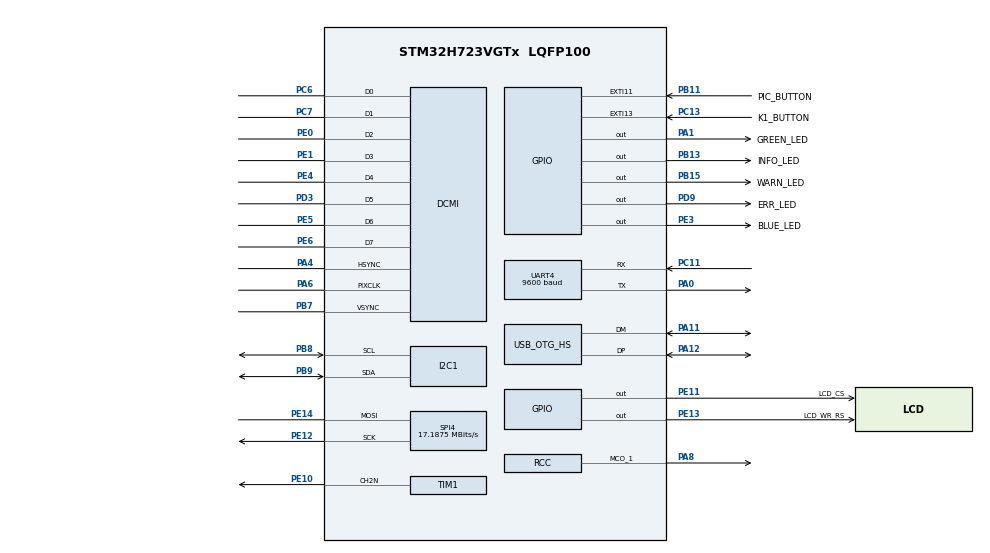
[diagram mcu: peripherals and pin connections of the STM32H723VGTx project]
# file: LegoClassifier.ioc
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CORTEX_M7.default_mode_Activation=1
DCMI.PCKPolarity=DCMI_PCKPOLARITY_RISING
Dma.DCMI.0.Direction=DMA_PERIPH_TO_MEMORY
Dma.DCMI.0.EventEnable=DISABLE
Dma.DCMI.0.FIFOMode=DMA_FIFOMODE_DISABLE
Dma.DCMI.0.Instance=DMA1_Stream0
Dma.DCMI.0.MemDataAlignment=DMA_MDATAALIGN_WORD
Dma.DCMI.0.MemInc=DMA_MINC_ENABLE
Dma.DCMI.0.Mode=DMA_CIRCULAR
Dma.DCMI.0.PeriphDataAlignment=DMA_PDATAALIGN_WORD
Dma.DCMI.0.PeriphInc=DMA_PINC_DISABLE
Dma.DCMI.0.Polarity=HAL_DMAMUX_REQ_GEN_RISING
Dma.DCMI.0.Priority=DMA_PRIORITY_MEDIUM
Dma.DCMI.0.RequestNumber=1
Dma.DCMI.0.SignalID=NONE
Dma.DCMI.0.SyncEnable=DISABLE
Dma.DCMI.0.SyncPolarity=HAL_DMAMUX_SYNC_NO_EVENT
Dma.DCMI.0.SyncRequestNumber=1
Dma.DCMI.0.SyncSignalID=NONE
Dma.Request0=DCMI
FREERTOS.Mutexes01=usb_mutex,Dynamic,NULL,Available;core_dump_mutex,Dynamic,NULL,Available
FREERTOS.Tasks01=defaultTask,0,6144,StartDefaultTask,Default,NULL,Static,defaultTaskBuffer,defaultTaskControlBlock
I2C1.Timing=0x60404E72
IWDG1.Prescaler=IWDG_PRESCALER_256
Mcu.Family=STM32H7
Mcu.Name=STM32H723VGTx
Mcu.Package=LQFP100
NVIC.DCMI_PSSI_IRQn=true\:5\:0\:false\:false\:true\:true\:true\:true\:true
NVIC.DMA1_Stream0_IRQn=true\:5\:0\:false\:false\:true\:true\:false\:true\:true
NVIC.EXTI15_10_IRQn=true\:5\:0\:false\:false\:true\:true\:true\:true\:true
NVIC.OTG_HS_IRQn=true\:5\:0\:false\:false\:true\:true\:false\:true\:true
NVIC.PriorityGroup=NVIC_PRIORITYGROUP_4
NVIC.TIM2_IRQn=true\:15\:0\:false\:false\:true\:false\:false\:true\:true
NVIC.TimeBase=TIM2_IRQn
NVIC.TimeBaseIP=TIM2
PA0.Mode=Asynchronous
PA0.Signal=UART4_TX
PA1.GPIO_Label=GREEN_LED
PA1.Signal=GPIO_Output
PA11.Mode=Device_Only_FS
PA11.Signal=USB_OTG_HS_DM
PA12.Mode=Device_Only_FS
PA12.Signal=USB_OTG_HS_DP
PA13(JTMS/SWDIO).Mode=Serial_Wire
PA13(JTMS/SWDIO).Signal=DEBUG_JTMS-SWDIO
PA14(JTCK/SWCLK).Mode=Serial_Wire
PA14(JTCK/SWCLK).Signal=DEBUG_JTCK-SWCLK
PA4.Mode=Slave_8_bits_External_Synchro
PA4.Signal=DCMI_HSYNC
PA6.Mode=Slave_8_bits_External_Synchro
PA6.Signal=DCMI_PIXCLK
PA8.Mode=Clock-out-1
PA8.Signal=RCC_MCO_1
PB11.GPIO_Label=PIC_BUTTON
PB11.GPIO_PuPd=GPIO_PULLDOWN
PB11.Signal=GPXTI11
PB13.GPIO_Label=INFO_LED
PB13.GPIO_PuPd=GPIO_PULLDOWN
PB13.Signal=GPIO_Output
PB15.GPIO_Label=WARN_LED
PB15.GPIO_PuPd=GPIO_PULLDOWN
PB15.Signal=GPIO_Output
PB7.Mode=Slave_8_bits_External_Synchro
PB7.Signal=DCMI_VSYNC
PB8.Mode=I2C
PB8.Signal=I2C1_SCL
PB9.Mode=I2C
PB9.Signal=I2C1_SDA
PC11.Mode=Asynchronous
PC11.Signal=UART4_RX
PC13.GPIO_Label=K1_BUTTON
PC13.GPIO_ModeDefaultEXTI=GPIO_MODE_IT_RISING
PC13.GPIO_PuPd=GPIO_PULLDOWN
PC13.Signal=GPXTI13
PC14-OSC32_IN.Mode=LSE-External-Oscillator
PC14-OSC32_IN.Signal=RCC_OSC32_IN
PC15-OSC32_OUT.Mode=LSE-External-Oscillator
PC15-OSC32_OUT.Signal=RCC_OSC32_OUT
PC6.Mode=Slave_8_bits_External_Synchro
PC6.Signal=DCMI_D0
PC7.Mode=Slave_8_bits_External_Synchro
PC7.Signal=DCMI_D1
PD3.Mode=Slave_8_bits_External_Synchro
PD3.Signal=DCMI_D5
PD9.GPIO_Label=ERR_LED
PD9.GPIO_PuPd=GPIO_PULLDOWN
PD9.Signal=GPIO_Output
PE0.Mode=Slave_8_bits_External_Synchro
PE0.Signal=DCMI_D2
PE1.Mode=Slave_8_bits_External_Synchro
PE1.Signal=DCMI_D3
PE10.Mode=PWM Generation2 CH2N
PE10.Signal=TIM1_CH2N
PE11.GPIO_Label=LCD_CS
PE11.Signal=GPIO_Output
PE12.Mode=Simplex_Bidirectional_Master
PE12.Signal=SPI4_SCK
PE13.GPIO_Label=LCD_WR_RS
PE13.Signal=GPIO_Output
PE14.Mode=Simplex_Bidirectional_Master
PE14.Signal=SPI4_MOSI
PE3.GPIO_Label=BLUE_LED
PE3.Signal=GPIO_Output
PE4.Mode=Slave_8_bits_External_Synchro
PE4.Signal=DCMI_D4
PE5.Mode=Slave_8_bits_External_Synchro
PE5.Signal=DCMI_D6
PE6.Mode=Slave_8_bits_External_Synchro
PE6.Signal=DCMI_D7
PH0-OSC_IN.Mode=HSE-External-Oscillator
PH0-OSC_IN.Signal=RCC_OSC_IN
PH1-OSC_OUT.Mode=HSE-External-Oscillator
PH1-OSC_OUT.Signal=RCC_OSC_OUT
ProjectManager.HeapSize=0x200
ProjectManager.StackSize=0x400
ProjectManager.TargetToolchain=CMake
RCC.ADCFreq_Value=50390625
RCC.APB1Freq_Value=137500000
RCC.APB2Freq_Value=137500000
RCC.APB3Freq_Value=137500000
RCC.APB4Freq_Value=137500000
RCC.CortexFreq_Value=550000000
RCC.D1PPRE=RCC_APB3_DIV2
RCC.D2PPRE1=RCC_APB1_DIV2
RCC.D2PPRE2=RCC_APB2_DIV2
RCC.D3PPRE=RCC_APB4_DIV2
RCC.DIVM1=2
RCC.DIVN1=44
RCC.DIVP1=1
RCC.DIVQ1=46
RCC.HCLKFreq_Value=275000000
RCC.HPRE=RCC_HCLK_DIV2
RCC.PLL2FRACN=0
RCC.PLL3FRACN=0
RCC.PLLFRACN=0
RCC.PLLSourceVirtual=RCC_PLLSOURCE_HSE
RCC.RCC_MCO1Source=RCC_MCO1SOURCE_HSI48
RCC.RCC_MCODiv1=RCC_MCODIV_4
RCC.SYSCLKFreq_VALUE=550000000
RCC.SYSCLKSource=RCC_SYSCLKSOURCE_PLLCLK
RCC.USBCLockSelection=RCC_USBCLKSOURCE_HSI48
RCC.USBFreq_Value=48000000
SPI4.BaudRatePrescaler=SPI_BAUDRATEPRESCALER_8
SPI4.CalculateBaudRate=17.1875 MBits/s
SPI4.DataSize=SPI_DATASIZE_8BIT
SPI4.Direction=SPI_DIRECTION_1LINE
SPI4.Mode=SPI_MODE_MASTER
SPI4.VirtualType=VM_MASTER
TIM1.Channel-PWM\ Generation2\ CH2N=TIM_CHANNEL_2
TIM1.OCNPolarity_2=TIM_OCNPOLARITY_LOW
TIM1.Period=1000-1
TIM1.Prescaler=14-1
UART4.BaudRate=9600
USB_DEVICE.CLASS_NAME_HS=CDC
USB_DEVICE.PRODUCT_STRING_CDC_HS=STM32 LegoClassifier
USB_DEVICE.VID=8743
USB_DEVICE.VirtualMode=Cdc
USB_DEVICE.VirtualModeHS=Cdc_HS
USB_OTG_HS.VirtualMode-Device_Only_FS=Device_Only_FS
VP_FREERTOS_VS_CMSIS_V1.Mode=CMSIS_V1
VP_IWDG1_VS_IWDG.Mode=IWDG_Activate
VP_MEMORYMAP_VS_MEMORYMAP.Mode=CurAppReg
VP_RTC_VS_RTC_Activate.Mode=RTC_Enabled
VP_RTC_VS_RTC_Calendar.Mode=RTC_Calendar
VP_SYS_VS_tim2.Mode=TIM2
VP_USB_DEVICE_VS_USB_DEVICE_CDC_HS.Mode=CDC_HS
board=custom

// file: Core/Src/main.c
/* USER CODE BEGIN Header */
/**
  ******************************************************************************
  * @file           : main.c
  * @brief          : Main program body
  ******************************************************************************
  * @attention
  *
  * Copyright (c) 2026 STMicroelectronics.
  * All rights reserved.
  *
  * This software is licensed under terms that can be found in the LICENSE file
  * in the root directory of this software component.
  * If no LICENSE file comes with this software, it is provided AS-IS.
  *
  ******************************************************************************
  */
/* USER CODE END Header */
#include "main.h"
#include "cmsis_os.h"
#include "dcmi.h"
#include "dma.h"
#include "i2c.h"
#include "iwdg.h"
#include "rtc.h"
#include "spi.h"
#include "tim.h"
#include "usart.h"
#include "usb_device.h"
#include "gpio.h"

/* USER CODE BEGIN Includes */
#include "app_entry.h"
/* USER CODE END Includes */

void SystemClock_Config(void);
static void MPU_Config(void);
void MX_FREERTOS_Init(void);

int main(void)
{

  /* MPU Configuration--------------------------------------------------------*/
  MPU_Config();

  /* MCU Configuration--------------------------------------------------------*/

  /* Reset of all peripherals, Initializes the Flash interface and the Systick. */
  HAL_Init();

  /* Configure the system clock */
  SystemClock_Config();

  /* Initialize all configured peripherals */
  MX_GPIO_Init();
  MX_DMA_Init();
  MX_I2C1_Init();
  MX_DCMI_Init();
  MX_SPI4_Init();
  MX_TIM1_Init();
  MX_IWDG1_Init();
  MX_RTC_Init();
  MX_UART4_Init();
  /* USER CODE BEGIN 2 */
  app_initiation();
  /* USER CODE END 2 */

  /* Call init function for freertos objects (in cmsis_os2.c) */
  MX_FREERTOS_Init();

  /* Start scheduler */
  osKernelStart();

  /* We should never get here as control is now taken by the scheduler */

  /* Infinite loop */
  while (1)
  {

  }
}

void SystemClock_Config(void)
{
  RCC_OscInitTypeDef RCC_OscInitStruct = {0};
  RCC_ClkInitTypeDef RCC_ClkInitStruct = {0};

  /** Supply configuration update enable
  */
  HAL_PWREx_ConfigSupply(PWR_LDO_SUPPLY);

  /** Configure the main internal regulator output voltage
  */
  __HAL_PWR_VOLTAGESCALING_CONFIG(PWR_REGULATOR_VOLTAGE_SCALE0);

  while(!__HAL_PWR_GET_FLAG(PWR_FLAG_VOSRDY)) {}

  /** Initializes the RCC Oscillators according to the specified parameters
  * in the RCC_OscInitTypeDef structure.
  */
  RCC_OscInitStruct.OscillatorType = RCC_OSCILLATORTYPE_HSI48|RCC_OSCILLATORTYPE_LSI
                              |RCC_OSCILLATORTYPE_HSE;
  RCC_OscInitStruct.HSEState = RCC_HSE_ON;
  RCC_OscInitStruct.LSIState = RCC_LSI_ON;
  RCC_OscInitStruct.HSI48State = RCC_HSI48_ON;
  RCC_OscInitStruct.PLL.PLLState = RCC_PLL_ON;
  RCC_OscInitStruct.PLL.PLLSource = RCC_PLLSOURCE_HSE;
  RCC_OscInitStruct.PLL.PLLM = 2;
  RCC_OscInitStruct.PLL.PLLN = 44;
  RCC_OscInitStruct.PLL.PLLP = 1;
  RCC_OscInitStruct.PLL.PLLQ = 46;
  RCC_OscInitStruct.PLL.PLLR = 2;
  RCC_OscInitStruct.PLL.PLLRGE = RCC_PLL1VCIRANGE_3;
  RCC_OscInitStruct.PLL.PLLVCOSEL = RCC_PLL1VCOWIDE;
  RCC_OscInitStruct.PLL.PLLFRACN = 0;
  if (HAL_RCC_OscConfig(&RCC_OscInitStruct) != HAL_OK)
  {
    Error_Handler();
  }

  /** Initializes the CPU, AHB and APB buses clocks
  */
  RCC_ClkInitStruct.ClockType = RCC_CLOCKTYPE_HCLK|RCC_CLOCKTYPE_SYSCLK
                              |RCC_CLOCKTYPE_PCLK1|RCC_CLOCKTYPE_PCLK2
                              |RCC_CLOCKTYPE_D3PCLK1|RCC_CLOCKTYPE_D1PCLK1;
  RCC_ClkInitStruct.SYSCLKSource = RCC_SYSCLKSOURCE_PLLCLK;
  RCC_ClkInitStruct.SYSCLKDivider = RCC_SYSCLK_DIV1;
  RCC_ClkInitStruct.AHBCLKDivider = RCC_HCLK_DIV2;
  RCC_ClkInitStruct.APB3CLKDivider = RCC_APB3_DIV2;
  RCC_ClkInitStruct.APB1CLKDivider = RCC_APB1_DIV2;
  RCC_ClkInitStruct.APB2CLKDivider = RCC_APB2_DIV2;
  RCC_ClkInitStruct.APB4CLKDivider = RCC_APB4_DIV2;

  if (HAL_RCC_ClockConfig(&RCC_ClkInitStruct, FLASH_LATENCY_3) != HAL_OK)
  {
    Error_Handler();
  }
  HAL_RCC_MCOConfig(RCC_MCO1, RCC_MCO1SOURCE_HSI48, RCC_MCODIV_4);
}

 /* MPU Configuration */

void MPU_Config(void)
{
  MPU_Region_InitTypeDef MPU_InitStruct = {0};

  /* Disables the MPU */
  HAL_MPU_Disable();

  /** Initializes and configures the Region and the memory to be protected
  */
  MPU_InitStruct.Enable = MPU_REGION_ENABLE;
  MPU_InitStruct.Number = MPU_REGION_NUMBER0;
  MPU_InitStruct.BaseAddress = 0x0;
  MPU_InitStruct.Size = MPU_REGION_SIZE_4GB;
  MPU_InitStruct.SubRegionDisable = 0x87;
  MPU_InitStruct.TypeExtField = MPU_TEX_LEVEL0;
  MPU_InitStruct.AccessPermission = MPU_REGION_NO_ACCESS;
  MPU_InitStruct.DisableExec = MPU_INSTRUCTION_ACCESS_DISABLE;
  MPU_InitStruct.IsShareable = MPU_ACCESS_SHAREABLE;
  MPU_InitStruct.IsCacheable = MPU_ACCESS_NOT_CACHEABLE;
  MPU_InitStruct.IsBufferable = MPU_ACCESS_NOT_BUFFERABLE;

  HAL_MPU_ConfigRegion(&MPU_InitStruct);
  /* Enables the MPU */
  HAL_MPU_Enable(MPU_PRIVILEGED_DEFAULT);

}

void HAL_TIM_PeriodElapsedCallback(TIM_HandleTypeDef *htim)
{
  if (htim->Instance == TIM2)
  {
    HAL_IncTick();
  }
}

void Error_Handler(void)
{
  /* USER CODE BEGIN Error_Handler_Debug */
  /* User can add his own implementation to report the HAL error return state */
  __disable_irq();
  while (1)
  {
    HAL_GPIO_TogglePin(ERR_LED_GPIO_Port, ERR_LED_Pin);
    HAL_Delay(200);
  }
  /* USER CODE END Error_Handler_Debug */
}

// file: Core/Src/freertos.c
/* USER CODE BEGIN Header */
/**
  ******************************************************************************
  * File Name          : freertos.c
  * Description        : Code for freertos applications
  ******************************************************************************
  * @attention
  *
  * Copyright (c) 2026 STMicroelectronics.
  * All rights reserved.
  *
  * This software is licensed under terms that can be found in the LICENSE file
  * in the root directory of this software component.
  * If no LICENSE file comes with this software, it is provided AS-IS.
  *
  ******************************************************************************
  */
/* USER CODE END Header */

#include "app_entry.h"
#include "FreeRTOS.h"
#include "task.h"
#include "main.h"
#include "cmsis_os.h"

osThreadId defaultTaskHandle;
uint32_t defaultTaskBuffer[ 6144 ];
osStaticThreadDef_t defaultTaskControlBlock;
osMutexId usb_mutexHandle;
osMutexId core_dump_mutexHandle;

void StartDefaultTask(void const * argument);

extern void MX_USB_DEVICE_Init(void);
void MX_FREERTOS_Init(void); /* (MISRA C 2004 rule 8.1) */

/* GetIdleTaskMemory prototype (linked to static allocation support) */
void vApplicationGetIdleTaskMemory( StaticTask_t **ppxIdleTaskTCBBuffer, StackType_t **ppxIdleTaskStackBuffer, uint32_t *pulIdleTaskStackSize );

/* USER CODE BEGIN GET_IDLE_TASK_MEMORY */
static StaticTask_t xIdleTaskTCBBuffer;
static StackType_t xIdleStack[configMINIMAL_STACK_SIZE];

void vApplicationGetIdleTaskMemory( StaticTask_t **ppxIdleTaskTCBBuffer, StackType_t **ppxIdleTaskStackBuffer, uint32_t *pulIdleTaskStackSize )
{
  *ppxIdleTaskTCBBuffer = &xIdleTaskTCBBuffer;
  *ppxIdleTaskStackBuffer = &xIdleStack[0];
  *pulIdleTaskStackSize = configMINIMAL_STACK_SIZE;
  /* place for user code */
}
/* USER CODE END GET_IDLE_TASK_MEMORY */

void MX_FREERTOS_Init(void) {
  /* Create the mutex(es) */
  /* definition and creation of usb_mutex */
  osMutexDef(usb_mutex);
  usb_mutexHandle = osMutexCreate(osMutex(usb_mutex));

  /* definition and creation of core_dump_mutex */
  osMutexDef(core_dump_mutex);
  core_dump_mutexHandle = osMutexCreate(osMutex(core_dump_mutex));

  /* Create the thread(s) */
  /* definition and creation of defaultTask */
  osThreadStaticDef(defaultTask, StartDefaultTask, osPriorityNormal, 0, 6144, defaultTaskBuffer, &defaultTaskControlBlock);
  defaultTaskHandle = osThreadCreate(osThread(defaultTask), NULL);

}

void StartDefaultTask(void const * argument)
{
  /* init code for USB_DEVICE */
  MX_USB_DEVICE_Init();
  /* USER CODE BEGIN StartDefaultTask */
  /* Infinite loop */
  for(;;)
  {
    app_loop();
    osDelay(1);
  }
  /* USER CODE END StartDefaultTask */
}
